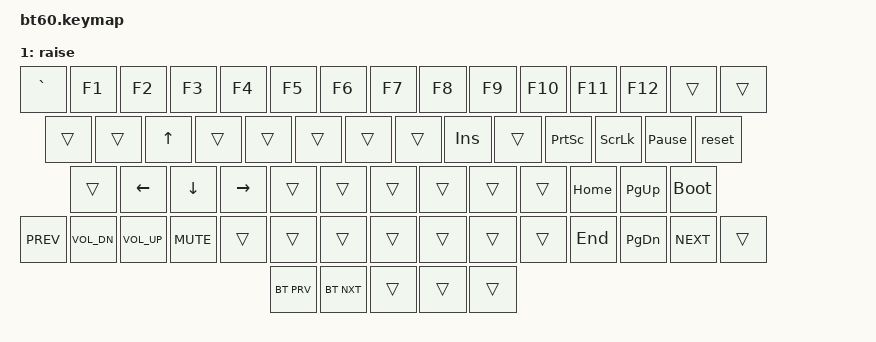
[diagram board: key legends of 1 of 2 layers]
#include <behaviors.dtsi>
#include <dt-bindings/zmk/keys.h>
#include <dt-bindings/zmk/bt.h>
#include <dt-bindings/zmk/rgb.h>
#include <dt-bindings/zmk/backlight.h>

/ {
	keymap {
		compatible = "zmk,keymap";

		default_layer {
			bindings = <
				&kp ESC &kp N1 &kp N2 &kp N3 &kp N4 &kp N5 &kp N6 &kp N7 &kp  N8   &kp  N9 &kp  N0  &kp MINUS &kp EQUAL &kp BSLH &kp GRAVE
				&kp TAB  &kp Q  &kp W  &kp E  &kp R  &kp T  &kp Y  &kp U  &kp  I    &kp  O  &kp  P   &kp LBKT &kp RBKT  &kp COMMA
				&kp LCTRL  &kp A  &kp S  &kp D  &kp F  &kp G  &kp H  &kp J  &kp  K    &kp  L  &kp SEMI &kp SQT           &kp RET
				&kp LSHFT  &kp Z  &kp X  &kp C  &kp V  &kp B  &kp N  &kp M  &kp COMMA &kp DOT &kp FSLH    &kp RSHFT  &mo 1
				         &kp LALT &kp LGUI           &kp SPACE                          &kp RALT  &mo 2
			>;
			sensor-bindings = <&inc_dec_kp C_VOL_UP C_VOL_DN>;
		};
		raise {
			bindings = <
				&kp GRAVE &kp F1 &kp F2 &kp F3 &kp F4 &kp F5 &kp F6 &kp F7 &kp  F8   &kp  F9 &kp  F10  &kp F11 &kp F12   &trans &trans
				&trans &trans &kp UP &trans &trans &trans &trans &trans &kp INS &trans &kp PSCRN &kp SLCK &kp PAUSE_BREAK &reset
				&trans    &kp LEFT &kp DOWN &kp RIGHT &trans &trans &trans &trans &trans &trans &kp HOME  &kp PG_UP   &bootloader
				&kp C_PREV &kp C_VOL_DN &kp C_VOL_UP &kp C_MUTE &trans &trans &trans &trans &trans &trans &trans &kp END &kp PG_DN  &kp C_NEXT &trans
				    &bt BT_PRV &bt BT_NXT          &trans                            &trans  &trans
			>;
			sensor-bindings = <&inc_dec_kp C_VOL_UP C_VOL_DN>;
		};
	};
};
